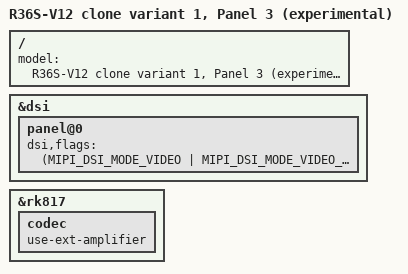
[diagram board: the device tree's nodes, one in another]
// SPDX-License-Identifier: (GPL-2.0+ OR MIT)
/*
 * EXPERIMENTAL - not tested on hardware by andr36oid. Keep a copy of the
 * files you replace so you can go back.
 *
 * EE clone "R36S-V12 2023-08-18 Variant 1 Panel 3 A": Variant 1 (G80) wiring
 * with the Panel 9 init sequence (the vendor labels it "Panel 3") at its stock
 * 30 MHz timing - which is panel9.dtsi's default, so no timing override is
 * needed. Like the Variant 1 Panel 8 board it needs a continuous (burst) DSI
 * clock and runs the speaker through an external amplifier.
 * Source: dArkOSen-R36S by djparentx (clone/R36S-V12 2023-08-18 Variant 1
 * Panel 3 A, rk3326-r36s-linux.dtb).
 */

/dts-v1/;
#include "rk3326-r36s-clone-ee.dtsi"
#include "rk3326-r36s-clone-panel9.dtsi"

/ {
	model = "R36S-V12 clone variant 1, Panel 3 (experimental)";
};

&dsi {
	panel@0 {
		dsi,flags = <(MIPI_DSI_MODE_VIDEO |
		      MIPI_DSI_MODE_VIDEO_BURST |
		      MIPI_DSI_MODE_EOT_PACKET |
		      MIPI_DSI_MODE_LPM)>;
	};
};

/* the speaker runs through an external amplifier (stock "use-ext-amplifier") */
&rk817 {
	codec {
		use-ext-amplifier;
	};
};
